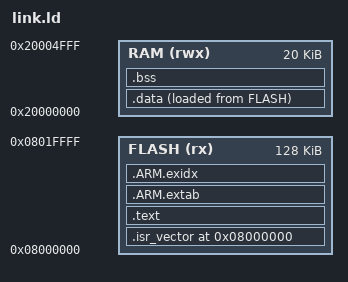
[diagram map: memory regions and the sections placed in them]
/* STM32F103-like memory layout for fixture builds */
ENTRY(main)

MEMORY
{
  FLASH (rx)  : ORIGIN = 0x08000000, LENGTH = 128K
  RAM   (rwx) : ORIGIN = 0x20000000, LENGTH = 20K
}

SECTIONS
{
  .isr_vector 0x08000000 :
  {
    KEEP(*(.isr_vector))
  } > FLASH

  .text :
  {
    *(.text*)
    *(.rodata*)
    . = ALIGN(4);
    _etext = .;
  } > FLASH

  .ARM.extab :
  {
    *(.ARM.extab* .gnu.linkonce.armextab.*)
  } > FLASH

  .ARM.exidx :
  {
    __exidx_start = .;
    *(.ARM.exidx*)
    __exidx_end = .;
  } > FLASH

  _sidata = LOADADDR(.data);

  .data :
  {
    . = ALIGN(4);
    _sdata = .;
    *(.data*)
    . = ALIGN(4);
    _edata = .;
  } > RAM AT> FLASH

  .bss :
  {
    . = ALIGN(4);
    _sbss = .;
    *(.bss*)
    *(COMMON)
    . = ALIGN(4);
    _ebss = .;
  } > RAM

  . = ALIGN(8);
  _estack = ORIGIN(RAM) + LENGTH(RAM);
}
